VERSION ""

NS_ :

BS_:

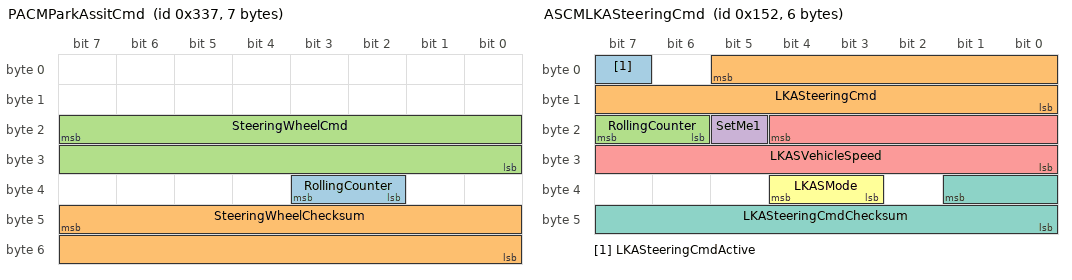
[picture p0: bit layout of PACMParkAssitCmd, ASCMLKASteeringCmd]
BO_ 823 PACMParkAssitCmd: 7 NEO
 SG_ RollingCounter : 35|2@0+ (1,0) [0|0] ""  NEO
 SG_ SteeringWheelChecksum : 47|16@0+ (1,0) [0|0] ""  NEO
 SG_ SteeringWheelCmd : 23|16@0+ (1,0) [0|0] ""  NEO

BO_ 560 EBCMRegen: 6 K17_EBCM
 SG_ Regen : 1|10@0+ (1,0) [0|0] ""  NEO

BO_ 338 ASCMLKASteeringCmd: 6 NEO
 SG_ LKASteeringCmdActive : 7|1@0+ (1,0) [0|0] ""  NEO
 SG_ LKASteeringCmd : 5|14@0- (1,0) [0|0] ""  NEO
 SG_ RollingCounter : 23|2@0+ (1,0) [0|0] ""  NEO
 SG_ SetMe1 : 21|1@0+ (1,0) [0|0] ""  NEO
 SG_ LKASVehicleSpeed : 20|13@0+ (0.22,0) [0|0] "kph" NEO
 SG_ LKASMode : 36|2@0+ (1,0) [0|0] ""  NEO
 SG_ LKASteeringCmdChecksum : 33|10@0+ (1,0) [0|0] ""  NEO

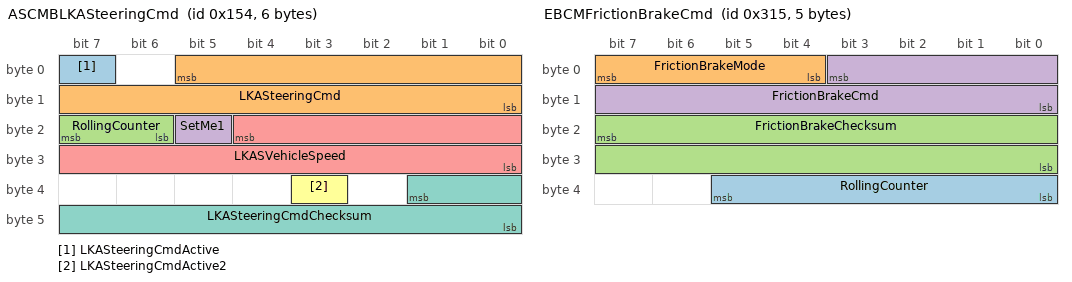
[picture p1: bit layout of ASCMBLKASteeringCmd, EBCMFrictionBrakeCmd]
BO_ 340 ASCMBLKASteeringCmd: 6 NEO
 SG_ LKASteeringCmdActive : 7|1@0+ (1,0) [0|0] ""  NEO
 SG_ LKASteeringCmd : 5|14@0- (1,0) [0|0] ""  NEO
 SG_ RollingCounter : 23|2@0+ (1,0) [0|0] ""  NEO
 SG_ SetMe1 : 21|1@0+ (1,0) [0|0] ""  NEO
 SG_ LKASVehicleSpeed : 20|13@0+ (0.22,0) [0|0] "kph" NEO
 SG_ LKASteeringCmdActive2 : 35|1@0+ (1,0) [0|0] ""  NEO
 SG_ LKASteeringCmdChecksum : 33|10@0+ (1,0) [0|0] ""  NEO

BO_ 368 EBCMFrictionBrakeStatus: 8 K17_EBCM
 SG_ FrictionBrakePressure : 23|16@0+ (1,0) [0|0] ""  NEO

BO_ 789 EBCMFrictionBrakeCmd: 5 K17_EBCM
 SG_ RollingCounter : 37|6@0+ (1,0) [0|0] ""  NEO
 SG_ FrictionBrakeMode : 7|4@0+ (1,0) [0|0] ""  NEO
 SG_ FrictionBrakeChecksum : 23|16@0+ (1,0) [0|0] ""  NEO
 SG_ FrictionBrakeCmd : 3|12@0- (1,0) [0|0] ""  NEO

BO_TX_BU_ 823 : K43_PSCM,NEO;
BO_TX_BU_ 789 : NEO,K17_EBCM;

BU_: XXX

CM_ SG_ 1024 RADAR_STATE "need to find out more diagnostic values";
VAL_ 780 CRUISE_SPEED 255 "no_speed" 252 "stopped";
VAL_ 780 HUD_LEAD 3 "acc_off" 2 "solid_car" 1 "dashed_car" 0 "no_car";
VAL_ 884 DASHBOARD_ALERT 0 "none" 51 "acc_problem" 55 "cmbs_problem" 75 "key_not_detected" 79 "fasten_seatbelt" 111 "lkas_problem" 131 "brake_system_problem" 132 "brake_hold_problem" 139 "tbd" 161 "door_open";
VAL_ 891 WIPERS 4 "High" 2 "Low" 0 "Off";

VAL_ 399 STEER_STATUS 6 "tmp_fault" 5 "fault_1" 4 "no_torque_alert_2" 3 "low_speed_lockout" 2 "no_torque_alert_1" 0 "normal";

VAL_ 829 BEEP 3 "single_beep" 2 "triple_beep" 1 "repeated_beep" 0 "no_beep";

VAL_ 401 GEAR_SHIFTER 32 "L" 16 "S" 8 "D" 4 "N" 2 "R" 1 "P";
VAL_ 401 GEAR 7 "L" 10 "S" 4 "D" 3 "N" 2 "R" 1 "P";
VAL_ 419 GEAR_SHIFTER 2 "S" 32 "D" 16 "N" 8 "R" 4 "P";
VAL_ 419 GEAR 26 "S" 20 "D" 19 "N" 18 "R" 17 "P";
VAL_ 545 ECON_ON_2 0 "off" 3 "on";
VAL_ 662 CRUISE_BUTTONS 7 "tbd" 6 "tbd" 5 "tbd" 4 "accel_res" 3 "decel_set" 2 "cancel" 1 "main" 0 "none";
VAL_ 662 CRUISE_SETTING 3 "distance_adj" 2 "tbd" 1 "lkas_button" 0 "none";
